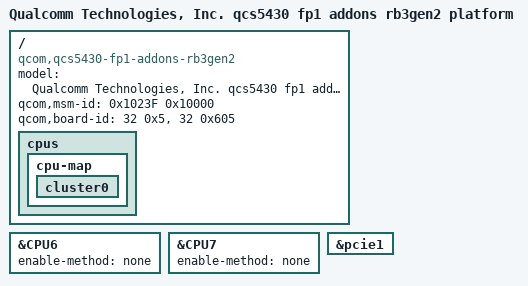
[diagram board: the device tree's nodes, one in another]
// SPDX-License-Identifier: BSD-3-Clause
/*
 * Copyright (c) 2024 Qualcomm Innovation Center, Inc. All rights reserved.
 */

/dts-v1/;

#include "qcs6490-addons-rb3gen2.dts"

/ {
	model = "Qualcomm Technologies, Inc. qcs5430 fp1 addons rb3gen2 platform";
	compatible = "qcom,qcs5430-fp1-addons-rb3gen2","qcom,qcs5430";
	qcom,msm-id = <0x1023F 0x10000>;
	qcom,board-id = <32 0x5>, <32 0x605>;

	cpus {
		cpu-map {
			cluster0 {
				/delete-node/ core6;
				/delete-node/ core7;
			};
		};
	};
};

&CPU6 {
	enable-method = "none";
};

&CPU7 {
	enable-method = "none";
};

&pcie1 {
	status = "ok";
};

